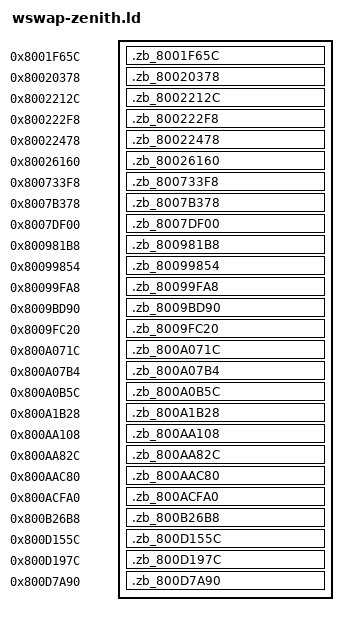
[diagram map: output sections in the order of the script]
/* Generated by tools/mod/zenith_pack.py from tools/mod/zenith_bins.txt and the sections of the Zenith build of
 * src/mod/wswap.c; do not edit by hand. Every output section is placed at the start of a range of unreferenced code of
 * BATTLE.PRG (tier 0/1) or SLUS_010.40 (tier 2) and must fit in it (tools/mod/build_zenith.sh checks that and that the
 * bytes it overwrites are the original ones). */
ENTRY(wswap_entry)
SECTIONS
{
    /* s_8001F65C   8001F65C..8001F6C4  104 of  104 bytes (tier 2): .z_swapAllowed2 */
    . = 0x8001F65C;
    .zb_8001F65C : SUBALIGN(4) { *(.z_swapAllowed2) }
    /* s_80020384   80020378..8002045C  220 of  228 bytes (tier 2): .z_slotMode */
    . = 0x80020378;
    .zb_80020378 : SUBALIGN(4) { *(.z_slotMode) }
    /* s_80022134   8002212C..80022214  232 of  232 bytes (tier 2): .z_entryCam */
    . = 0x8002212C;
    .zb_8002212C : SUBALIGN(4) { *(.z_entryCam) }
    /* s_80022304   800222F8..80022444  328 of  332 bytes (tier 2): .z_entryMode, .z_lab */
    . = 0x800222F8;
    .zb_800222F8 : SUBALIGN(4) { *(.z_entryMode) *(.z_lab) }
    /* s_80022484   80022478..80022564  216 of  236 bytes (tier 2): .z_shieldSwap */
    . = 0x80022478;
    .zb_80022478 : SUBALIGN(4) { *(.z_shieldSwap) }
    /* s_80026164   80026160..80026264  252 of  260 bytes (tier 2): .z_assign */
    . = 0x80026160;
    .zb_80026160 : SUBALIGN(4) { *(.z_assign) }
    /* e_800733F8   800733F8..80073484  140 of  140 bytes (tier 0): .z_wfp_look */
    . = 0x800733F8;
    .zb_800733F8 : SUBALIGN(4) { *(.z_wfp_look) }
    /* b_8007B378   8007B378..8007B410  152 of  152 bytes (tier 1): .z_slotPress */
    . = 0x8007B378;
    .zb_8007B378 : SUBALIGN(4) { *(.z_slotPress) }
    /* b_8007DF00   8007DF00..8007DF40   64 of   64 bytes (tier 1): .text */
    . = 0x8007DF00;
    .zb_8007DF00 : SUBALIGN(4) { *(.text) }
    /* b_800981B8   800981B8..8009820C   84 of   84 bytes (tier 1): .z_swapAllowed3, .z_pal */
    . = 0x800981B8;
    .zb_800981B8 : SUBALIGN(4) { *(.z_swapAllowed3) *(.z_pal) }
    /* e_80099854   80099854..80099960  264 of  268 bytes (tier 0): .z_entryPad */
    . = 0x80099854;
    .zb_80099854 : SUBALIGN(4) { *(.z_entryPad) }
    /* e_80099FA8   80099FA8..8009A028  128 of  128 bytes (tier 0): .z_startSwap */
    . = 0x80099FA8;
    .zb_80099FA8 : SUBALIGN(4) { *(.z_startSwap) }
    /* e_8009BD90   8009BD90..8009BE5C  200 of  204 bytes (tier 0): .z_wswap_entry, .z_equippedSlot */
    . = 0x8009BD90;
    .zb_8009BD90 : SUBALIGN(4) { *(.z_wswap_entry) *(.z_equippedSlot) }
    /* b_8009FC20   8009FC20..8009FC60   64 of   64 bytes (tier 1): .z_twoHanded */
    . = 0x8009FC20;
    .zb_8009FC20 : SUBALIGN(4) { *(.z_twoHanded) }
    /* e_800A071C   800A071C..800A0768   76 of   76 bytes (tier 0): .z_inSlot */
    . = 0x800A071C;
    .zb_800A071C : SUBALIGN(4) { *(.z_inSlot) }
    /* b_800A07B4   800A07B4..800A07FC   72 of   72 bytes (tier 1): .z_swapAllowed */
    . = 0x800A07B4;
    .zb_800A07B4 : SUBALIGN(4) { *(.z_swapAllowed) }
    /* e_800A0B5C   800A0B5C..800A0BE0  124 of  132 bytes (tier 0): .z_entryMsg */
    . = 0x800A0B5C;
    .zb_800A0B5C : SUBALIGN(4) { *(.z_entryMsg) }
    /* e_800A1B28   800A1B28..800A1B9C  116 of  116 bytes (tier 0): .z_modeFlags */
    . = 0x800A1B28;
    .zb_800A1B28 : SUBALIGN(4) { *(.z_modeFlags) }
    /* e_800AA108   800AA108..800AA290  392 of  392 bytes (tier 0): .z_beginSwap */
    . = 0x800AA108;
    .zb_800AA108 : SUBALIGN(4) { *(.z_beginSwap) }
    /* b_800AA82C   800AA82C..800AA850   36 of   36 bytes (tier 1): .z_msgOff */
    . = 0x800AA82C;
    .zb_800AA82C : SUBALIGN(4) { *(.z_msgOff) }
    /* e_800AAC80   800AAC80..800AACDC   88 of   92 bytes (tier 0): .z_drawHint */
    . = 0x800AAC80;
    .zb_800AAC80 : SUBALIGN(4) { *(.z_drawHint) }
    /* b_800ACFA0   800ACFA0..800AD008  104 of  104 bytes (tier 1): .z_shieldBind */
    . = 0x800ACFA0;
    .zb_800ACFA0 : SUBALIGN(4) { *(.z_shieldBind) }
    /* e_800B26B8   800B26B8..800B28A8  492 of  496 bytes (tier 0): .z_entryLoad, .z_hint */
    . = 0x800B26B8;
    .zb_800B26B8 : SUBALIGN(4) { *(.z_entryLoad) *(.z_hint) }
    /* e_800D155C   800D155C..800D1678  280 of  284 bytes (tier 0): .z_drawSmall */
    . = 0x800D155C;
    .zb_800D155C : SUBALIGN(4) { *(.z_drawSmall) }
    /* e_800D197C   800D197C..800D1B18  404 of  412 bytes (tier 0): .z_wslot_label, .bss */
    . = 0x800D197C;
    .zb_800D197C : SUBALIGN(4) { *(.z_wslot_label) *(.bss*) *(COMMON) LONG(0); }
    /* b_800D7A90   800D7A90..800D7AB4   36 of   36 bytes (tier 1): .z_swapLR */
    . = 0x800D7A90;
    .zb_800D7A90 : SUBALIGN(4) { *(.z_swapLR) }
    /DISCARD/ : { *(.reginfo) *(.MIPS.abiflags) *(.pdr) *(.gnu.attributes) *(.comment) *(.mdebug*) *(.data) }
}
